# MSS_SPI register map
Vendor: Texas Instruments
Registers are 32-bit, access per field, no defined reset value unless marked. A register's access mark holds for its fields unless they carry their own. Offsets are as the file gives them; [hi:lo] are bit positions; lines under a group give offsets from that group; {n}, {i} and the like mark numbered series; 'fields as' and 'values as' point back to an identical list.

## MSS_SPI (part 3 of 3)
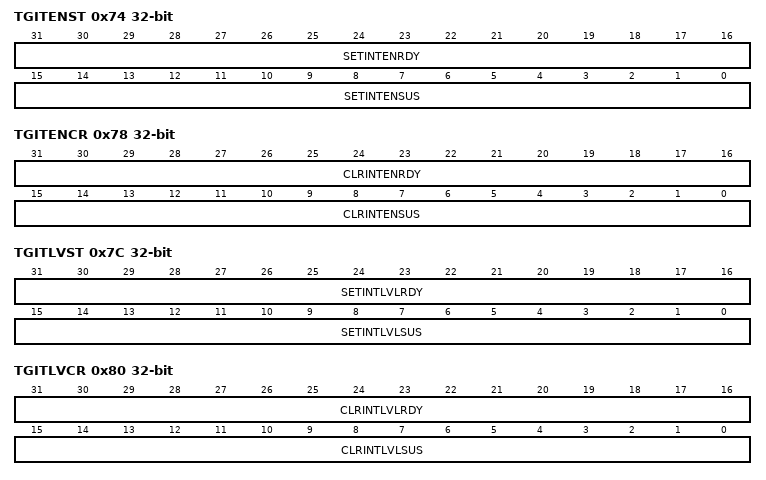
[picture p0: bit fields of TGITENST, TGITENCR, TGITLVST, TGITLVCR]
0x74 TGITENST rw — MibSPI Transfer Group Interrupt Enable Set Register
  [31:16] SETINTENRDY — Transfer group interrupt set (enable) when transfer finished. Write: 1 = Enables the “The Transfer group x completed “ interrupt Interrupt gets generated when Transfer Group x gets completed. 0 = Has no effect. Read: 1 = “The Transfer group x completed “ interrupt is enabled Interrupt gets generated when Transfer Group x gets completed. 0 = “The Transfer group x completed” interrupt is disabled Interrupt does not get generated when Transfer Group x gets completed
  [15:0] SETINTENSUS — Transfer group interrupt set (enable) when transfer suspended Write: 1 = Enables the “The Transfer group x suspended “ interrupt Interrupt gets generated when Transfer Group x gets suspended. 0 = Has no effect. Read: 1 = “The Transfer group x suspended “ interrupt is enabled Interrupt gets generated when Transfer Group x gets suspended. 0 = “The Transfer group x suspended” interrupt is disabled Interrupt does not get generated when Transfer Group x gets suspended
0x78 TGITENCR rw — MibSPI Transfer Group Interrupt Enable Clear Register
  [31:16] CLRINTENRDY — Transfer group interrupt clear (disable) when transfer finished. Write: 1 = Disables the “The Transfer group x completed “ interrupt Interrupt does not get generated when Transfer Group x gets completed. 0 = Has no effect. Read: 1 = “The Transfer group x completed “ interrupt is enabled Interrupt gets generated when Transfer Group x gets completed. 0 = “The Transfer group x completed” interrupt is disabled Interrupt does not get generated when Transfer Group x gets completed
  [15:0] CLRINTENSUS — Transfer group interrupt clear (disable) when transfer suspended Write: 1 = Disables the “The Transfer group x suspended “ interrupt Interrupt does not get generated when Transfer Group x gets suspended. 0 = Has no effect. Read: 1 = “The Transfer group x suspended “ interrupt is enabled Interrupt gets generated when Transfer Group x gets suspended. 0 = “The Transfer group x suspended” interrupt is disabled Interrupt does not get generated when Transfer Group x gets suspended
0x7C TGITLVST rw — MibSPI Transfer Group Interrupt Level Set Register
  [31:16] SETINTLVLRDY — Transfer group completed” Interrupt Level set register Write: 1 = Sets the “The Transfer group x completed “ interrupt to line INT1 0 = Has no effect. Read: 1 = “The Transfer group x completed “ interrupt is set to line INT1 0 = “The Transfer group x completed “ interrupt is set to line INT0
  [15:0] SETINTLVLSUS — Transfer group suspended” interrupt Level set rigester Write: 1 = Sets the “The Transfer group x suspended “ interrupt to line INT1 0 = Has no effect. Read: 1 = “The Transfer group x suspended “ interrupt is set to line INT1 0 = “The Transfer group x suspended “ interrupt is set to line INT0
0x80 TGITLVCR rw — MibSPI Transfer Group Interrupt Level Clear Register
  [31:16] CLRINTLVLRDY — Transfer group completed” Interrupt Level clear register Write: 1 = Sets the “The Transfer group x completed “ interrupt to line INT0 0 = Has no effect. Read: 1 = “The Transfer group x completed “ interrupt is set to line INT1 0 = “The Transfer group x completed “ interrupt is set to line INT0
  [15:0] CLRINTLVLSUS — Transfer group suspended” interrupt Level clear register Write: 1 = Sets the “The Transfer group x suspended “ interrupt to line INT0 0 = Has no effect. Read: 1 = “The Transfer group x suspended “ interrupt is set to line INT1 0 = “The Transfer group x suspended “ interrupt is set to line INT0
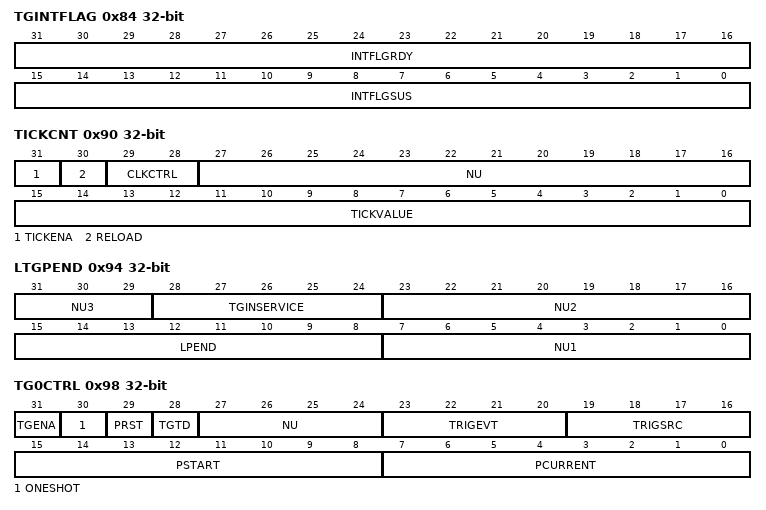
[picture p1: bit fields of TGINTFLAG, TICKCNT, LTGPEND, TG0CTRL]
0x84 TGINTFLAG ro — Transfer Group Interrupt Flag Register
  [31:16] INTFLGRDY — Transfer group interrupt flag for “transfer finished” interrupt. Read: 1 =A “transfer finished” interrupt from transfer group x occurred. No matter whether the interrupt is enabled or disabled (INTENRDYx = don’t care) or whether the interrupt is mapped to line INT0 or INT1, INTFLGRDYx is set right after the transfer from transfer group x is finished. 0 =No “transfer finished” interrupt occurred since last clearing of the flag INTFLGRDYx. Write: 1 = Clears the corresponding bit flag. 0 = Has no effect.
  [15:0] INTFLGSUS — Transfer group interrupt flag for “transfer suspend” interrupt. Read: 1 =A “transfer suspended” interrupt from transfer group x occurred. No matter whether the interrupt is enabled or disabled (INTENSUSx = don’t care) or whether the interrupt is mapped to line INT0 or INT1, INTFLGSUSx is set right after the transfer from transfer group x is suspended. 0 =No ”transfer suspended” interrupt occurred since last clearing of the flag INTFLGSUSx. Note: Read Clear Behavior Reading the interrupt vector registers TGINTVECT0 or TGINTVECT1 automatically clears the interrupt flag bit INTFLGRDYx referenced by the vector number given by INTVECT0/INTVECT1 bits, if SUSPEND0/SUPEND1 bit in the Vector registers is ‘0’.
0x90 TICKCNT — Tick Count Register
  [31] TICKENA rw — Tick counter enable. 1 =The MibSPI internal tick counter is enabled and is clocked by the clock source selected by CLKCTRL[1:0]. When the tick counter is enabled it starts down-counting from its current value. When TICKENA goes from “0” to “1” the tick counter is automatically loaded with the TICKVALUE. 0 =The MibSPI internal tick counter is disabled. The counter value remains unchanged. Note: When the tick counter is disabled the trigger signal is forced low.
  [30] RELOAD ro — Re-load tick counter. RELOAD is a set-only bit, i.e. writing a “1” to it automatically reloads the Tick Counter with the value stored in TICKVALUE. Reading RELOAD always returns a “0”. Note: When the tick counter is reloaded by the RELOAD bit, the trigger signal is not toggled.
  [29:28] CLKCTRL rw — Tick counter clock source control. CLKCTRL[1:0] defines the clock source that is used to clock the MibSPI internal tick counter.CLKCTRL[1:0] Description 00b SPICLK of Data word format 0 is selected as clock source of tick counter 01b SPICLK of Data word format 1 is selected as clock source of tick counter 10b SPICLK of Data word format 2 is selected as clock source of tick counter 11b SPICLK of Data word format 3 is selected as clock source of tick counter
  [27:16] NU ro — Reserved.Reads return ‘0’ and writes have no effect
  [15:0] TICKVALUE rw — Initial value for tick counter. TICKVALUE stores the initial value for the tick counter. The tick counter is loaded with TICKVALUE every time an under-flow condition occurs and every time the RELOAD flag is set by the host
0x94 LTGPEND — Last Transfer Group End Pointer
  [31:29] NU3 ro — Reserved.Reads return ‘0’ and writes have no effect
  [28:24] TGINSERVICE ro — Transfer Group currently being serviced by the Sequencer. Read-Only field indicating the current Transfer Group that is being serviced. This field can generally be used for code debug purpose. Read Value:TG IN SERVICE[4:0] Description 00000b No Transfer Group is being serviced by the Sequencer 00001b Transfer Group0 is being serviced by the Sequencer ... ... 10000b Transfer Group15 is being serviced by the Sequencer 10001b - 11111b Invalid values
  [23:16] NU2 ro — Reserved.Reads return ‘0’ and writes have no effect
  [15:8] LPEND rw — Last Transfer Group End Pointer Usually the transfer group end address (PEND) is inherently defined by the start value of the starting pointer of the subsequent transfer group (PSTART). The transfer group ends at the buffer one before the next transfer group starts (PEND[x]=PSTART[x+1] - 1). For a full configuration of MibSPI, the 15th transfer group has no subsequent transfer group, i.e. no end address is inherently defined. Therefore LPEND has to be programmed to specify explicitly the end address of the 15th transfer group. Number of Transfer Groups implemented in a MibSPI can vary from one MibSPI to another since it is a generic parameter based implementation. If in a MibSPI, only 4 Transfer Groups are implemented, then the PEND of the 4th TG is defined by LPEND values defined in this LTGPEND register.
  [7:0] NU1 ro — Reserved.Reads return ‘0’ and writes have no effect
0x98 TG0CTRL — MibSPI Transfer Group Control Register The number of transfer groups is scalable by design up to a maximum of 16. Depending on the implementation the number of transfer groups and hence the number of transfer group control register may vary. Each transfer group can be configured via one dedicated control register. The register description below shows one exemplary control register(x) which is identical for all transfer groups. E.g. the control register for transfer group 2 is named “TG2CTRL” and is located at address base0+98h+4*2.
  [31] TGENA rw — Transfer Group Enable. 1 =The corresponding transfer group is enabled. If the correct event (TRIGEVTx) occurs at the selected source (TRIGSRCx) a group transfer is initiated if no higher priority transfer group is in active transfer mode or if one or more higher priority Transfer Groups are in transfer suspend mode. If higher priority Transfer Groups (TG) are in transfer mode, then the newly enabled TG will wait till all of the higher priority TG transfers are completed. 0 =The corresponding transfer group is disabled. Disabling a transfer group while a transfer is ongoing, will finish the ongoing buffer transfer but not the whole group transfer
  [30] ONESHOT rw — Single transfer for this Transfer Group group. 1 =A transfer from the corresponding transfer group will be performed only once (= one shot) after a valid trigger event at the selected trigger source. After the transfer is finished the TGENAx control bit will be cleared by the MibSPI and therefore no additional transfer can be triggered before the host enables the transfer group again. This oneshot mode ensures that after one group transfer the host has enough time to read the received data and to provide new transmit data. 0 =The corresponding transfer group initiates a transfer every time a trigger event occurs and TGENA is set.
  [29] PRST rw — transfer group Pointer Reset mode. With PRST, the way of resolving trigger events during an ongoing transfer from the concerned transfer group can be configured. This bit is meaningful only for Level Triggered Transfer Groups. Edge triggered TGs cannot be re-started before their completion by another edge. PRST bit will have no effect on this behavior. 1 =The corresponding transfer group pointer (PCURRENTx) will be reset to the start address (PSTARTx) when a valid trigger event occurs at the selected trigger source while a transfer from the same transfer group is ongoing. I.e. every trigger event resets PCURRENTx no matter whether the concerned transfer group is in transfer mode or not. The trigger events have priority over the ongoing transfer. 0 =If a trigger event occurs during a transfer from the concerned transfer group, the event is ignored and is not stored internally. The transfer group transfer has priority over additional trigger events.
  [28] TGTD ro — Transfer group triggered. This bit is read-only. 1 =The transfer group has been triggered and is either currently in service or waiting for servicing. 0 =The corresponding transfer group has not been triggered or is no more waiting for service. Use the “TG IN SERVICE” field in LTGPEND register to determine the exact Transfer Group being currently serviced
  [27:24] NU ro — Reserved.Reads return ‘0’ and writes have no effect
  [23:20] TRIGEVT rw — Type of trigger event. After reset, the trigger event types of all transfer groups are set to inactive TypesTRIGEVTx[3:0] Type Description 0000b never 0001b rising edge A rising edge (0 to 1) at the selected trigger source (TRIGSRCx) initiates a transfer from the corresponding transfer group 0010b falling edge A falling edge (1 to 0) at the selected trigger source (TRIGSRCx) initiates a transfer from the corresponding transfer group 0011b both edges Rising and falling edges at the selected trigger source (TRIGSRCx) initiates a transfer from the corresponding transfer group 0100b reserved 0101b high-active Repetitive group transfer while trigger is high: While the selected trigger source (TRIGSRCx) is at a logic high level (1) the group transfer is continued and at the end of one group transfer restarted at the beginning. If ONESHOTx is set the transfer is performed only once. If the logic level changes to low (0) during an ongoing group transfer, the whole group transfer will be stopped. 0110b low-active Repetitive group transfer while trigger is low: While the selected trigger source (TRIGSRCx) is at a logic low level (0) the group transfer is continued and at the end of one restarted at the beginning. If ONESHOTx is set the transfer is performed only once. If the logic level changes to high (1) during an ongoing group transfer, the whole group transfer will be stopped. 0111b always A repetitive group transfer will be performed. Setting ONESHOTx allows a software controlled single transfer modea a. By setting the TRIGSRC to 0000b, the TRIGEVT to ALWAYS (0111b) the ONESHOT bit to 1. This allows a software control trigger on this Transfer Group. Then by setting the TGENA bit, the Transfer Group is immediately triggered. . If ONESHOTx is cleared a continuous mode for this Transfer Group is selected.1xxxb reserved
  [19:16] TRIGSRC rw — Trigger source. After reset the trigger sources of all transfer groups are disabled. Table 22. Trigger SourcesTRIGSRCx[3:0] Type Description 0000b disabled 0001b EXT0 MibSPI external trigger source 0. Source has to be defined individually for each Microcontroller derivative (e.g. HET I/O channel, event pin, etc.). 0010b EXT1 MibSPI external trigger source 1. Source has to be defined individually for each Microcontroller derivative (e.g. HET I/O channel, event pin, etc.). 0011b EXT2 MibSPI external trigger source 2. Source has to be defined individually for each Microcontroller derivative (e.g. HET I/O channel, event pin, etc.). 0100b EXT3 MibSPI external trigger source 3. Source has to be defined individually for each Microcontroller derivative (e.g. HET I/O channel, event pin, etc.). ... ... ... 1110b EXT13 MibSPI external trigger source 13. Source has to be defined individually for each Microcontroller derivative (e.g. HET I/O channel, event pin, etc.). 1111b TICK MibSPI internal periodic event trigger. The tick counter can initiate periodic group transfers.
  [15:8] PSTART rw — transfer group start address. PSTARTx stores the start address of the corresponding transfer group. The corresponding end address is inherently defined by the subsequent transfer groups start address minus one (PENDx[TGx] = PSTARTx[TGx+1]-1). PSTARTx is copied into PCURRENTx when: o the transfer group is enabled o the end of the transfer group is reached during a transfer o a trigger event occurs while PRST is set to 1
  [7:0] PCURRENT ro — transfer group pointer to current buffer. PCURRENT is read-only. PCURRENTx stores the address (0...127/255) of the buffer that is currently transferred or that will be transferred after a trigger event occurs (if PRSTx=0) or after the transfer group resumes from suspend to wait mode. If the transfer group switches mode from active transfer mode to “suspend to wait”, PCURRENTx keeps the address of the currently Suspended buffer. After the transfer group resumes from “suspend to wait” mode the next buffer will be transferred. I.e. no buffer data is multiply transferred or not at all transferred due to “suspend to wait” mode.
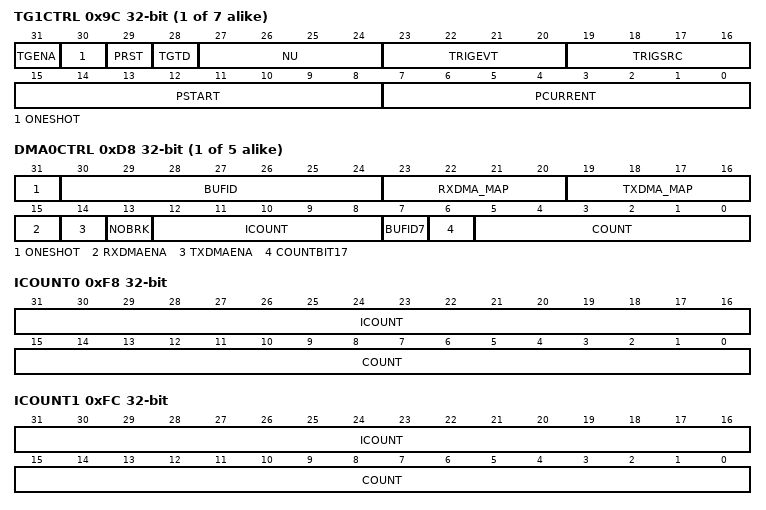
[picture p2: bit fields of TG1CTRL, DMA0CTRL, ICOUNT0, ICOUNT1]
{0x98+4i} TG{i}CTRL (i=1..7) — MibSPI Transfer Group Control Register
  fields as TG0CTRL
{0xD8+4i} DMA{i}CTRL (i=0..4) — MibSPI DMA Channel Control Register
  [31] ONESHOT rw — Auto-disable of DMA channel after ICOUNT+1 transfers. 1 =ONESHOTx allows a block transfer of defined length (ICOUNTx+1) mainly controlled by the MibSPI and not by the DMA controller. After ICOUNTx +1 transfers the enable bits RXDMAENAx and TXDMAENAx are automatically cleared by the MibSPI, hence no more DMA requests are generated. In conjunction with NOBRKx, a burst transfer can be initiated without any other transfer through another buffer. 0 =The length of the block transfer is fully controlled by the DMA controller. The enable bits RXDMAENAx and TXDMAENAx are not modified by the MibSPI.
  [30:24] BUFID rw — Buffer utilized for DMA transfer. BUFIDx defines the buffer that is utilized for the DMA transfer. In order to synchronize the transfer with the DMA controller with the NOBRK condition the “suspend to wait until...” modes must be used (for more details refer to Section 8.53.1).
  [23:20] RXDMA_MAP rw — Receive data DMA Request Map Each MibSPI DMA channel can be linked to two physical DMA Request lines of the DMA controller. One request line for receive data and the other for request line for transmit data. RXDMA_MAPx[3:0] defines the number of the physical DMA Request line that is connected to the receive path of the MibSPI DMA channel. If RXDMAENAx and TXDMAENAx are both set to ‘1’, then RXDMA_MAPx[3:0] shall differ from TXDMA_MAPx[3:0] and shall differ from any other used physical DMA Request line. Otherwise unexpected interference may occur.
  [19:16] TXDMA_MAP rw — Transmit data DMA channel Each MibSPI DMA channel can be linked to two physical DMA Request lines of the DMA controller. ne request line for receive data and the other for request line for transmit data. TXDMA_MAPx[3:0] defines the number of the physical DMA Request line that is connected to the transmit path of the MibSPI DMA channel. If RXDMAENAx and TXDMAENAx are both set then TXDMA_MAPx[3:0] shall differ from RXDMA_MAPx[3:0] and shall differ from any other used physical DMA Request line. Otherwise unexpected interference may occur.
  [15] RXDMAENA rw — Receive data DMA channel enable. 1 =The physical DMA Request line for the receive path is enabled. The first DMA request pulse is generated after the first transfer from the referenced buffer (BUFIDx) is finished. The concerned buffer should be configured in the mode “skip until RXEMPTY is set” or “suspend to wait until RXEMPTY is set” in order to ensure synchronization between DMA controller and MibSPI sequencer. 0 =No DMA request upon new receive data.
  [14] TXDMAENA rw — Transmit data DMA channel enable. 1 =The physical DMA Request line for the transmit path is enabled. The first DMA request pulse is generated right after setting TXDMAENAx to load the first transmit data. The concerned buffer should be configured in the mode “skip until TXFULL is set” or “suspend to wait until TXFULL is set” in order to ensure synchronization between DMA controller and MibSPI sequencer. 0 =No DMA request upon new transmit data
  [13] NOBRK rw — Non-interleaved DMA block transfer(Master mode only). 1 =NOBRKx ensures that ICOUNTx+1 data transfers are performed from the buffer referenced by BUFIDx without a data transfer from any other buffer. The sequencer remains at the DMA buffer until ICOUNTx+1 transfers have been processed. E.g: this can be used to generate a burst transfer to one device without disabling the chip select signal in-between (the concerned buffer has to be configured with CSHOLD=1). Another example would be to have a defined block data transfer in slave mode, synchronous to the master SPI. Triggering of higher priority transfer groups or enabling of higher priority DMA channels will not interrupt NOBRK block transfer. 0 =The DMA transfers through the buffer referenced by BUFIDx are interleaved by data transfers from other active buffers or transfer groups. Every time the sequencer checks the DMA buffer, it performs one transfer and then steps to the next buffer
  [12:8] ICOUNT rw — Initial Count of DMA transfers ICOUNTx[4:0] is used to preset the transfer counter COUNTx[4:0]. Every time COUNTx[4:0] hits zero it is reloaded with ICOUNTx[4:0]. The real number of transfer equals ICOUNTx[4:0] plus one. If ONESHOTx is set, ICOUNTx[4:0] defines the number of DMA transfers that are performed before the MibSPI automatically disables the DMA channels. If NOBRKx is set, ICOUNTx[4:0] defines the number of DMA transfers that are performed in one sequence without a transfer from any other buffer
  [7] BUFID7 rw — Extended bit of BUFIDx field when Extended Buffer feature is implemented. This bit represents the 8th bit of BUFID field such that any buffers between 127-255 can be configured as DMA capable buffers
  [6] COUNTBIT17 ro — The 17th bit of COUNT field of DMAxCOUNT register. This bit is useful only when ICOUNTx in DMAxCOUNT register is programmed to be 0xFFFF. During all other values, this bit remains to be ‘0’.
  [5:0] COUNT ro — Actual number of remaining DMA transfer COUNTx[5:0] is a read-only bit field. It comprises the actual number of DMA transfers that remain, until the DMA channel is disabled if ONESHOTx is set.
0xF8 ICOUNT0 — MibSPI DMAxCOUNT
  [31:16] ICOUNT rw — Initial Number of DMA transfers. ICOUNTx is used to preset the transfer counter COUNTx. Every time COUNTx hits zero it is reloaded with ICOUNTx. The real number of transfer equals ICOUNTx plus one. If ONESHOTx is set, ICOUNTx defines the number of DMA transfers that are performed before the MibSPI automatically disables the DMA channels. If NOBRKx is set, ICOUNTx defines the number of DMA transfers that are performed in one sequence without a transfer from any other buffer
  [15:0] COUNT ro — Actual number of remaining DMA transfer COUNTx is a read-only bit field. It comprises the actual number of DMA transfers that remain, until the DMA channel is disabled if ONESHOTx is set. Since the real COUNTx is always ICLOUNTx +1, the 17th bit of COUNTx is available on DMAxCTRL(6) bit.
0xFC ICOUNT1 — MibSPI DMAxCOUNT
  fields as ICOUNT0
0x100 ICOUNT2 16-bit ro — MibSPI DMAxCOUNT
  [15:0] COUNT — Actual number of remaining DMA transfer COUNTx is a read-only bit field. It comprises the actual number of DMA transfers that remain, until the DMA channel is disabled if ONESHOTx is set. Since the real COUNTx is always ICLOUNTx +1, the 17th bit of COUNTx is available on DMAxCTRL(6) bit.
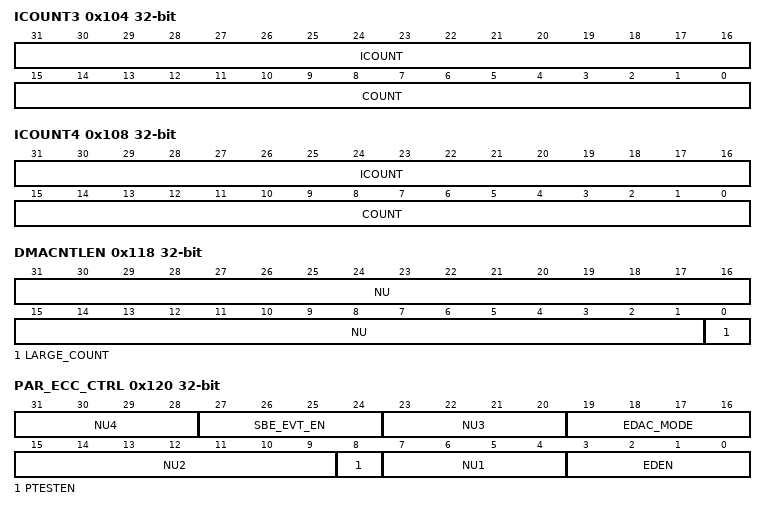
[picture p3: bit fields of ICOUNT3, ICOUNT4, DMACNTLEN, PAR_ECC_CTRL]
0x104 ICOUNT3 — MibSPI DMAxCOUNT
  fields as ICOUNT0
0x108 ICOUNT4 — MibSPI DMAxCOUNT
  fields as ICOUNT0
0x118 DMACNTLEN — DMA LARGE COUNT register
  [31:1] NU ro — Reserved.Reads return ‘0’ and writes have no effect.
  [0] LARGE_COUNT rw — 0: Writes to the DMAxCTRL register will modify the ICOUNT value. Reading ICOUNT and COUNT can be done from the DMAxCTRL register. The DMAxCOUNT register should not be used since any write to this register will be overwritten by a subsequent write to DMAxCTRL register to set the TXDMAENA or RXDMAENA bits. 1: Writes to the DMAxCTRL register will not modify the ICOUNT value. The ICOUNT value must be written to in the DMAxCOUNT register before the RXDMAENA or TXDMAENA bits are set in the DMAxCTRL register. The DMAxCOUNT register should be used for reading COUNT or ICOUNT.
0x120 PAR_ECC_CTRL — Parity/ECC Control Register
  [31:28] NU4 ro — Reserved.Reads return ‘0’ and writes have no effect.
  [27:24] SBE_EVT_EN rw — Single Bit Error Event Enable This bit controls the generation of Error signaling (on MIBSPI_SBERR port) whenever a Single Bit Errors (SBE) is detected on TXRAM/RXRAM. This signal can be used to generate interrupt if required. Write: 0101 - Disable Error Event indication upon detection of SBE on TXRAM/RXRAM 1010 - Enable Error Event upon detection of SBE on TXRAM/RXRAM All other values - writes are ignored and the values are not updated into this field. The state of the feature remains unchanged. Read: Returns the current value of the field
  [23:20] NU3 ro — Reserved.Reads return ‘0’ and writes have no effect.
  [19:16] EDAC_MODE rw — Error Detection And Correction Mode These bits determine whether Single Bit Errors (SBE) detected by the SECDED block will be corrected or not. Write: 0101 - Disable correction of SBE detected by the SECDED block 1010 - Enable correction of SBE detected by the SECDED block All other values - writes are ignored and the values are not updated into this field. The state of the feature remains unchanged. Read: Returns the current value of the field
  [15:9] NU2 ro — Reserved.Reads return ‘0’ and writes have no effect.
  [8] PTESTEN rw — Parity/ECC memory Test Enable. This bit, maps the parity/ecc bits corresponding to Multibuffer RAM locations into the peripheral RAM frame to make them accessible by the CPU. User and privilege mode (read): 0 = parity/ecc bits are not memory mapped 1 = parity/ecc bits are memory mapped Privilege mode (write): 0 = disable memory mapping of Parity/ECC locations 1 = enable memory mapping of Parity/ECC locations
  [7:4] NU1 ro — Reserved.Reads return ‘0’ and writes have no effect.
  [3:0] EDEN rw — Error Detection Enable These bits enable Parity/ECC Error Detection. Write: 0101: Disables Parity/ECC Error Detection Logic(default) Others : Enables Parity/ECC Error Detection Logic. Read: Returns the current value of this field
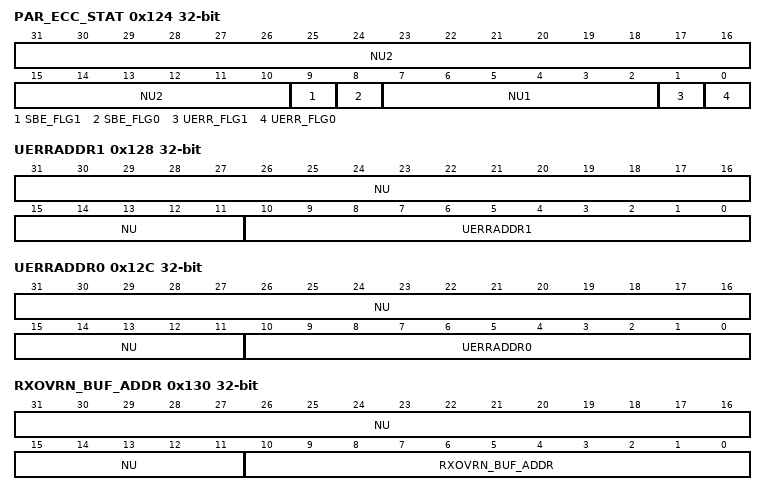
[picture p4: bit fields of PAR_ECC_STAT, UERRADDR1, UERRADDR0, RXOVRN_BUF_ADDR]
0x124 PAR_ECC_STAT ro — Parity/ECC Status Register
  [31:10] NU2 — Reserved.Reads return ‘0’ and writes have no effect.
  [9] SBE_FLG1 — Single Bit Error in RXRAM. This flag indicates if a single bit ECC Error ocurred on reading RXRAM Read: 0 = No error occured. 1 = Single bit error is detected in RXRAM and the address is captured in SBERRADDR1 register. Write: 0 = No effect. 1 = Clears the bit.
  [8] SBE_FLG0 — Single Bit Error in TXRAM. This flag indicates if a single bit ECC Error ocurred on reading TXRAM Read: 0 = No error occured. 1 = Single bit error is detected in TXRAM and the address is captured in SBERRADDR0 register. Write: 0 = No effect. 1 = Clears the bit.
  [7:2] NU1 — Reserved.Reads return ‘0’ and writes have no effect.
  [1] UERR_FLG1 — Uncorrectable Parity or double bit ECC error detection flag This flag indicates if a Parity or double bit ECC error ocurred on reading RXRAM When this bit is read: 0 = No error occured. 1 = Error detected and the address is captured in UERRADDR1 register. When write to this bit with: 0 = No effect. 1 = Clears the bit
  [0] UERR_FLG0 — Uncorrectable Parity or double bit ECC error detection flag This flag indicates if a Parity or ECC error ocurred on reading TXRAM When this bit is read: 0 = No error occured. 1 = Error detected and the address is captured in UERRADDR0 register. When write to this bit with: 0 = No effect. 1 = Clears the bit.
0x128 UERRADDR1 ro — Uncorrectable Parity or double bit ECC error Address Register - RXRAM
  [31:11] NU — Reserved.Reads return ‘0’ and writes have no effect.
  [10:0] UERRADDR1 — Uncorrectable Parity or double bit ECC error address This register holds the address of the RAM location if a parity or double bit ECC error is detected when reading the MibSPI (Receive) RXRAM. The address captured is byte alligned when RAM Parity Check is supported. This error address is frozen from being updated until it is read by the VBUS host. Reading this register clears its contents to the default value The default value is 0x400 if Extended Buffer feature is enabled, else it is 0x200 Writes to this register are ignored
0x12C UERRADDR0 ro — Uncorrectable Parity or double bit ECC error address register - TXRAM
  [31:11] NU — Reserved.Reads return ‘0’ and writes have no effect.
  [10:0] UERRADDR0 — Uncorrectable Parity or double bit ECC error address This register holds the address when a parity error is generated while reading the MibSPI (Transmit) TXRAM. The TXRAM can be read either by CPU or by the MibSPI Sequencer FSM logic for transmission. The address captured is byte alligned. This error address is frozen from being updated until it is read by the VBUSP host. Reading this register clears its contents to the default value of 0x000. Writes to this register are ignored.
0x130 RXOVRN_BUF_ADDR ro — Receive RAM Overrun Buffer Address Register
  [31:11] NU — Reserved.Reads return ‘0’ and writes have no effect.
  [10:0] RXOVRN_BUF_ADDR — Address of the RAM location of RXRAM for which an Overwrite occured. This address value will show only the offset address of the RAM location in the Multibuffer RAM address space. Refer to the device Spec for the actual absolute address of RXRAM. Content of this register are valid only when any of the TGINTVECT0 or TGINTVECT1 and SPIFLG registers show an RXOVRN error vector while in Multibuffer mode. If there are multiple Overrun errors, then this register holds address of first overrun address until it is read.
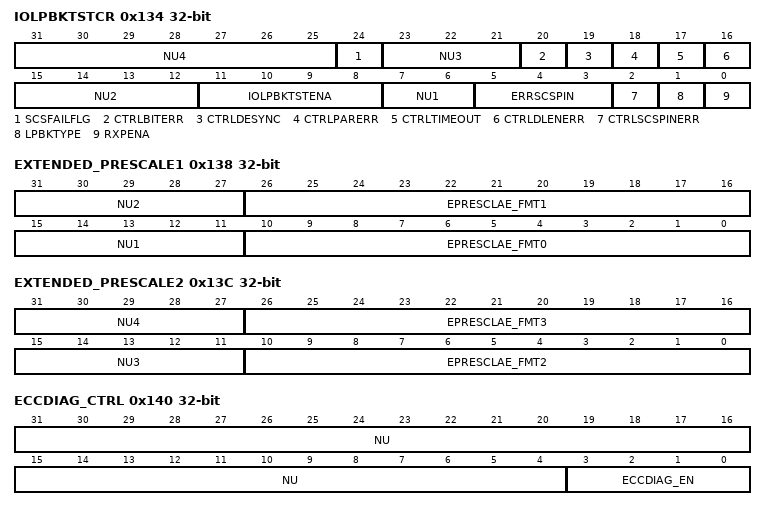
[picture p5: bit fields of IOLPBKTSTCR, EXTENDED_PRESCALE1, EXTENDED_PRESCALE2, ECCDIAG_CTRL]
0x134 IOLPBKTSTCR access not given — SPI/MibSPI IO Loopback Test Control Register This register controls test mode for I/O pins. It also controls whether loop-back should be digital or analog ones in this test mode. In addition it contains control bits to induce some of the error condition into the module. These are to be used for test purpose only. All the control/status bits in this register are valid only when IO LPBK TST ENA field is set to “1010”.
  [31:25] NU4 ro — Reserved. Reads return ‘0’ and writes have no effect.
  [24] SCSFAILFLG — Bit indicating a failure on SPISCS pin compare during analog loopback during IO Loopback Test mode. Read 1 = A comparison between the internal CSNR field and the analog looped back value of SPISCS[7:0] pins failed. A stuck-at fault is detected on one of the SPISCS[7:0]. Comparison is done only on the pins which are configured as functional and during transfer operation. 0 = No miscompares on any of the 8 chipselect pin value comparison with the internal Chipselect number CSNR during transfers. Write 1 = Clear this Flag bit. 0 = No effect.
  [23:21] NU3 ro — Reserved. Reads return ‘0’ and writes have no effect.
  [20] CTRLBITERR rw — Controls inducing of BITERR during IO Loopback Test mode. 1 = The value of incoming data from the loopback Transmit pin is flipped. 0 = No affect on BIT ERROR.
  [19] CTRLDESYNC rw — Controls inducing of DESYNC Error during IO Loopback Test mode. 1 = Forces the incoming SPIENA pin (if functional) to remain ‘0’ even after the transfer complete. This forcing will be retained until the Kernel reaches IDLE state. 0 = No affect on DESYNC Error.
  [18] CTRLPARERR rw — Controls inducing of Parity Error during IO Loopback Test mode. 1 = Flips the Parity Polarity signal being used for transmit parity generation logic 0 = No affect on Parity Error
  [17] CTRLTIMEOUT rw — Controls inducing of TIMEOUT Error during IO LoopbacK Test mode. 1 = Forces the incoming SPIENA pin (if functional) to remain ‘1’ when transmission is initiated. The forcing will be retained until the Kernel reaches IDLE state. 0 = No affect on TIMEOUT Error.
  [16] CTRLDLENERR rw — Controls inducing of Data Length Error during IO Loopback Test mode. 1 = When in Master mode, forces the SPIENA pin(if functional) to ‘1’ when the module starts Shifting the data. When in Slave mode, forces the incoming SPISCS pin(if functional) to ‘1’ when the module starts shifting the data.. 0 = No affect on Data Length Error.
  [15:12] NU2 ro — Reserved. Reads return ‘0’ and writes have no effect.
  [11:8] IOLPBKTSTENA rw — Module I/O Loopback Test Enable Key User and Privileged mode reads. Write access only in Privileged mode. Write: 1010 = I/O DFT is enabled All other values = I/O DFT is disabled Read: 1010 = I/O DFT is enabled All other values = I/O DFT is disabled
  [7:6] NU1 ro — Reserved. Reads return ‘0’ and writes have no effect.
  [5:3] ERRSCSPIN rw — Inject Error on ChipSelect Pin. The value in this field is decoded to find out the ChipSelect pin on which to inject an error. During the analog loopback of IO Loopback Test mode if CTRL SCS PIN ERR bit is set to ‘1’, then the chipselect pin selected by this field is forced to the opposite of its original CSNR bit. 000 - Select SPISCS[0] for injecting error 001 - Select SPISCS[1] for injecting error . 111 - Select SPISCS[7] for injecting error
  [2] CTRLSCSPINERR rw — Control bit to enable the injection of an error on SPISCS[7:0] pins. Individual pins of SPISCS[7:0] can be choosen using ERR SCS PIN. 1 = Enable the error inducing logic to the SPISCS pins. 0 = Disable the error inducing logic.
  [1] LPBKTYPE rw — Module IO Loopback Type (Analog/Digital). User and Privileged mode reads. Write access only in Privileged mode. Write/Read : 1 = Analog loopback is enabled in module I/O DFT mode when IOLPBKTSTENA = 1010) 0 = Digital loopback is enabled in module I/O DFT mode when IOLPBKTSTENA = 1010
  [0] RXPENA rw — Module Analog loopback through Receive Pin Enable. User and Privileged mode reads. Write only in privileged mode: Write/Read : 1 = Analog loopback through receive pin 0 = Analog loopback through transmit pin. This bit is valid only when LPBK TYPE = ‘1’ which chooses Analog loopback mode.
0x138 EXTENDED_PRESCALE1 — SPI/MibSPI Extended Prescale Register 1 (EXTENDED_PRESCALE1 for SPIFMT0 and SPIFMT1) This register provides an extended Prescale values for SPICLK generation to be able to interface with much slower SPI Slaves. This is an extension of SPIFMT0 and SPIFMT1 registers. For example, EPRESCALE_FMT1(7:0) of EXTENDED_PRESCALE1 and PRESCALE1(7:0) of SPIFMT1 register will always reflect the same contents. Similarly EPRESCALE_FMT0(7:0) and PRESCALE0(7:0) of SPIFMT0 reflect the same contents.
  [31:27] NU2 ro — Reserved. Reads return ‘0’ and writes have no effect.
  [26:16] EPRESCLAE_FMT1 rw — Extended Prescale value for SPIFMT1. EPRESCALE_FMT1 can be modified in privilege mode only. EPRESCALE_FMT1 determines the bit transfer rate of Data Format 1 if the SPI/MibSPI is the network master. If the SPI / MibSPI is configured as slave, this field DOES NOT NEED to be configured. These EPRESCALE_FMT1(7:0) bits and PRESCALE1(7:0) bits of SPIFMT1 register will point to the same physically implemented register. Refer to Figure 56 for a graphical representation of the implementation. Write : This register field should be written if a SPICLK prescaler of more VBUSPCLK/256 is required. This field provides a prescaler of up to VBUSPCLK/2048 for SPICLK. Writing to this register field will also get reflected in SPIFMT1(15:8). Read : Reading this field will reflect the PRESCALE value based on the last written register field i.e., EXTENDED_PRESCALE1(26:16) or SPIFMT1(15:8) register. Note: If Extended Prescaler is required, it should be ensured that EXTENDED_PRESCALE1 register is programmed after SPIFMT1 register is programmed. This is to ensure that the final SPICLK prescale value is controlled by EXTENDED_PRESCALE1 register when a prescale of more 256 is intended on SPICLK. BRFormatx = VBUSPCLK/(EXTENDEDPRESCALEy+1) When EPRESCALE_FMTy (y=1,2) is set to zero(0), the SPI clock rate defaults to VBUSPCLK/2.
  [15:11] NU1 ro — Reserved. Reads return ‘0’ and writes have no effect.
  [10:0] EPRESCLAE_FMT0 rw — EPRESCALE_FMT0 can be modified in privilege mode only. EPRESCALE_FMT0 determines the bit transfer rate of Data Format 0 if the SPI is the network master. If the SPI / MibSPI is configured as slave, this field DOES NOT NEED to be configured. These EPRESCALE_FMT0(7:0) bits and PRESCALE0(7:0) bits of SPIFMT0 register will point to the same physically implemented register. Refer to Figure 56 for a graphical representation of the implementation. Write : This register field should be written if a SPICLK prescaler of more VBUSPCLK/256 is required. This field provides a prescaler of up to VBUSPCLK/2048 for SPICLK. Writing to this register field will also get reflected in SPIFMT0(15:8). Read : Reading this field will reflect the PRESCALE value based on the last written register field i.e., EPRESCALE0(26:16) or SPIFMT0(15:8) register. Note: If Extended Prescaler is required, it should be ensured that EXTENDED_PRESCALE1 register is programmed after SPIFMT0 register is programmed. This is to ensure that the final SPICLK prescale value is controlled by EXTENDED_PRESCALE1 register when a prescale of more 256 is intended on SPICLK.
0x13C EXTENDED_PRESCALE2 — SPI/MibSPI Extended Prescale Register 2 (EXTENDED_PRESCALE2 for SPIFMT2 and SPIFMT3) This register provides an extended Prescale values for SPICLK generation to be able to interface with much slower SPI Slaves. This register is an extension of SPIFMT2 and SPIFMT3 registers. For example, EPRESCALE_FMT2(7:0) of EXTENDED_PRESCALE2 and PRESCALE2(7:0) of SPIFMT2 register will always reflect the same contents. Similarly EPRESCALE_FMT3(7:0) and PRESCALE3(7:0) of SPIFMT3 reflect the same contents.
  [31:27] NU4 ro — Reserved. Reads return ‘0’ and writes have no effect.
  [26:16] EPRESCLAE_FMT3 rw — EPRESCALE_FMT3 can be modified in privilege mode only. EPRESCALE_FMT3 determines the bit transfer rate of Data Format 3 if the SPI is the network master. If the SPI / MibSPI is configured as slave, this field DOES NOT NEED to be configured. These EPRESCALE_FMT3(7:0) bits and PRESCALE3(7:0) bits of SPIFMT3 register will point to the same physically implemented register. Refer to Figure 56 for a graphical representation of the implementation. Write : This register field should be written if a SPICLK prescaler of more VBUSPCLK/256 is required. This field provides a prescaler of up to VBUSPCLK/2048 for SPICLK. Writing to this register field will also get reflected in SPIFMT3(15:8). Read : Reading this field will reflect the PRESCALE value based on the last written register field i.e., EPRESCALE3(26:16) or SPIFMT3(15:8) register. Note: If Extended Prescaler is required, it should be ensured that EXTENDED_PRESCALE2 register is programmed after SPIFMT3 register is programmed. This is to ensure that the final SPICLK prescale value is controlled by EXTENDED_PRESCALE2 register when a prescale of more 256 is intended on SPICLK.
  [15:11] NU3 ro — Reserved. Reads return ‘0’ and writes have no effect.
  [10:0] EPRESCLAE_FMT2 rw — EPRESCALE_FMT2 can be modified in privilege mode only. EPRESCALE_FMT2 determines the bit transfer rate of Data Format 2 if the SPI is the network master. If the SPI / MibSPI is configured as slave, this field DOES NOT NEED to be configured. These EPRESCALE_FMT2(7:0) bits and PRESCALE2(7:0) bits of SPIFMT2 register will point to the same physically implemented register. Refer to Figure 56 for a graphical representation of the implementation. Write : This register field should be written if a SPICLK prescaler of more VBUSPCLK/256 is required. This field provides a prescaler of up to VBUSPCLK/2048 for SPICLK. Writing to this register field will also get reflected in SPIFMT3(15:8). Read : Reading this field will reflect the PRESCALE value based on the last written register field i.e., EXTENDED_PRESCALE2(26:16) or SPIFMT2(15:8) register. Note: If Extended Prescaler is required, it should be ensured that EXTENDED_PRESCALE2 register is programmed after SPIFMT2 register is programmed. This is to ensure that the final SPICLK prescale value is controlled by EXTENDED_PRESCALE2 register when a prescale of more 256 is intended on SPICLK.
0x140 ECCDIAG_CTRL — ECC Diagnostic Control register
  [31:4] NU ro — Reserved. Reads return ‘0’ and writes have no effect.
  [3:0] ECCDIAG_EN rw — ECC Diagnostic mode Enable Key bits. 0101 : Diagnostic mode is enabled. Writes and reads from ECC bits allowed from the ECC address space. Refer to Section 9 for details on ECC/Parity address space. Others : Diagnostic mode is disabled. No writes to ECC bits are ignored, reads return ‘0’.
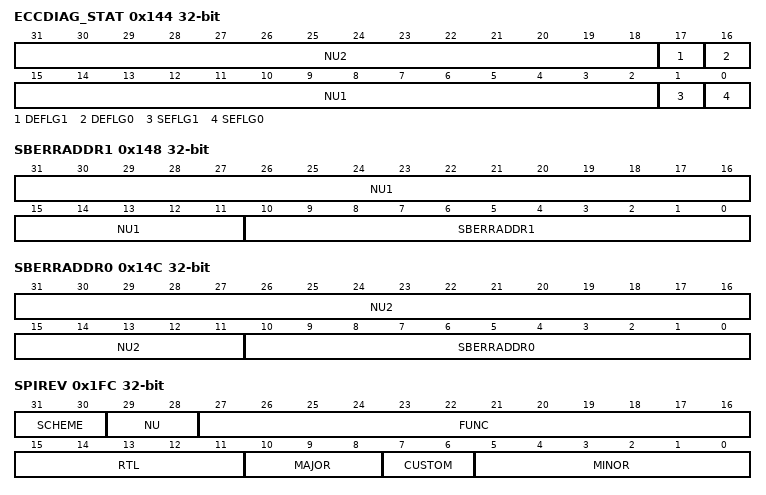
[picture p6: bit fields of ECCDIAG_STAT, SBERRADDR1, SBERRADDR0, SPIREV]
0x144 ECCDIAG_STAT ro — ECC Diagnostic Status register
  [31:18] NU2 — Reserved. Reads return ‘0’ and writes have no effect.
  [17] DEFLG1 — Double bit error flag for RXRAM 1 - A double bit Error is detected for RXRAM bank during diagnostic mode tests. 0 - No error. A write ‘1’ to this bit will clear the bit.
  [16] DEFLG0 — Double bit error flag for TXRAM 1 - A double bit Error is detected for TXRAM bank during diagnostic mode tests. 0 - No error. A write ‘1’ to this bit will clear the bit.
  [15:2] NU1 — Reserved. Reads return ‘0’ and writes have no effect.
  [1] SEFLG1 — Single bit error flag for RXRAM 1 - A Single bit Error is detected for RXRAM bank during diagnostic mode tests. 0 - No error. A write ‘1’ to this bit will clear the bit.
  [0] SEFLG0 — Single bit error flag for TXRAM 1 - A Single bit Error is detected for TXRAM bank during diagnostic mode tests. 0 - No error. A write ‘1’ to this bit will clear the bit.
0x148 SBERRADDR1 ro — Single Bit Error Address Register - RXRAM
  [31:11] NU1 — Reserved.Reads return ‘0’ and writes have no effect.
  [10:0] SBERRADDR1 — Single Bit ECC Error Address This register holds the address of the RAM location when a single bit error is generated by SECDED block while reading the MibSPI (Receive) RXRAM. This error address is frozen from being updated until it is read by the VBUS host. Reading this register clears its contents to the default value The default value is 0x400 if Extended Buffer feature is enabled, else it is 0x200 Writes to this register are ignored.
0x14C SBERRADDR0 ro — Single Bit ECC Error Address Register - TXRAM
  [31:11] NU2 — Reserved.Reads return ‘0’ and writes have no effect.
  [10:0] SBERRADDR0 — Single Bit ECC Error Address This register holds the address when a single bit error is generated from SECDED block while reading the MibSPI (Transmit) TXRAM. The TXRAM can be read either by CPU or by the MibSPI Sequencer logic for transmission. This error address is frozen from being updated until it is read by the VBUSP host. Reading this register clears its contents to the default value of 0x000. Writes to this register are ignored.
0x1FC SPIREV ro — SPI / MibSPI Revision ID Register
  [31:30] SCHEME — Identification Scheme Used to distinguish different ID schemes. Reads 0x01
  [29:28] NU — Reserved.Reads return ‘0’ and writes have no effect.
  [27:16] FUNC — Indicates functionally equivalent module family Reads 0xA05
  [15:11] RTL — RTL version number Read value will provide an approximate RTL revision number. The design release version can be obtained from the device specification
  [10:8] MAJOR — Major Revision number Reads 0x3
  [7:6] CUSTOM — Indicates device specific implementation Reads 0x0
  [5:0] MINOR — Minor Revision number Reads 0x8
